# M2003 register map
File version: 1.0
Registers are 32-bit, read-write, reset 0x0 unless marked. A register's access mark holds for its fields unless they carry their own. Offsets are from the block's base; [hi:lo] are bit positions; {n}, {i} and the like mark numbered series.

## TMR2 — TIMER Register Map
Base 0x40051000
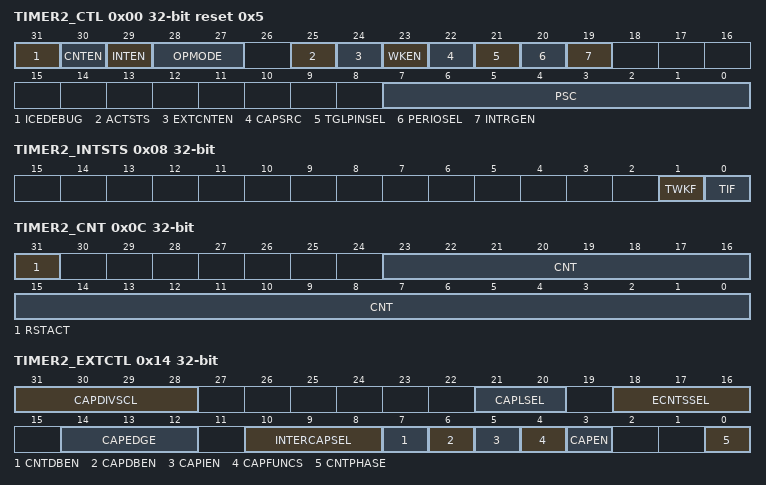
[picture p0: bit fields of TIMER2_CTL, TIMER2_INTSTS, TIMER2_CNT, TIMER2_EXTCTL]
0x00 TIMER2_CTL reset 0x5 — Timer2 Control Register
  [31] ICEDEBUG — ICE Debug Mode Acknowledge Disable Bit (Write Protect). TIMER counter will keep going no matter CPU is held by ICE or not. Note: This bit is write protected. Refer to the SYS_REGLCTL register.
    0=ICE debug mode acknowledgement effects TIMER counting; 1=ICE debug mode acknowledgement Disabled
  [30] CNTEN — Timer Counting Enable Bit. Note 3: Set enable/disable this bit needs 2 * TMR_CLK period to become active, user can read ACTSTS (TIMERx_CTL[25]) to check enable/disable command is completed or not.
    0=Stops/Suspends counting; 1=Starts counting
  [29] INTEN — Timer Interrupt Enable Bit. Note: If this bit is enabled, when the timer time-out interrupt flag TIF is set to 1, the timer interrupt signal is generated and inform to CPU.
    0=Timer time-out interrupt Disabled; 1=Timer time-out interrupt Enabled
  [28:27] OPMODE — Timer Counting Mode Select
    0=The timer controller is operated in One-shot mode; 1=The timer controller is operated in Periodic mode; 2=The timer controller is operated in Toggle-output mode; 3=The timer controller is operated in Continuous Counting mode
  [25] ACTSTS ro — Timer Active Status Bit (Read Only). This bit indicates the 24-bit up counter status. Note: This bit may active when CNT 0 transition to CNT 1.
    0=24-bit up counter is not active; 1=24-bit up counter is active
  [24] EXTCNTEN — Event Counter Mode Enable Bit. This bit is for external counting pin function enabled. Note: When timer is used as an event counter, this bit should be set to 1 and select PCLK as timer clock source.
    0=Event counter mode Disabled; 1=Event counter mode Enabled
  [23] WKEN — Wake-up Function Enable Bit. If this bit is set to 1, while timer interrupt flag TIF (TIMERx_INTSTS[0]) is 1 and INTEN (TIMERx_CTL[29]) is enabled, the timer interrupt signal will generate a wake-up trigger event to CPU.
    0=Wake-up function Disabled if timer interrupt signal generated; 1=Wake-up function Enabled if timer interrupt signal generated
  [22] CAPSRC — Capture Pin Source Selection. Note: Set this bit to 0 .
    0=Capture Function source is from TMx_EXT (x= 0~3) pin
  [21] TGLPINSEL — Toggle-output Pin Select
    0=Toggle mode output to TMx (Timer Event Counter Pin); 1=Toggle mode output to TMx_EXT (Timer External Capture Pin)
  [20] PERIOSEL — Periodic Mode Behavior Selection Enable Bit. If updated CMPDAT value CNT, CNT will be reset to default value.
    0=The behavior selection in periodic mode is Disabled; 1=The behavior selection in periodic mode is Enabled
  [19] INTRGEN — Inter-timer Trigger Mode Enable Bit. Setting this bit will enable the inter-timer trigger capture function. The Timer0/2 will be in event counter mode and counting with external clock source or event.Also, Timer1/3 will be in trigger-counting mode of capture function. Note: For Timer1/3, this bit is ineffective and the read back value is always 0.
    0=Inter-Timer Trigger Capture mode Disabled; 1=Inter-Timer Trigger Capture mode Enabled
  [7:0] PSC — Prescale Counter. Note: Update prescale counter value will reset internal 8-bit prescale counter and 24-bit up counter value.
0x04 TIMER2_CMP — Timer2 Comparator Register
  [23:0] CMPDAT — Timer Comparator Value. CMPDAT is a 24-bit compared value register. When the internal 24-bit up counter value is equal to CMPDAT value, the TIF (TIMERx_INTSTS[0] Timer Interrupt Flag) will set to 1. Note 1: Never write 0x0 or 0x1 in CMPDAT field, or the core will run into unknown state. Note 2: When timer is operating at continuous counting mode, the 24-bit up counter will keep counting continuously even if user writes a new value into CMPDAT field. But if timer is operating at other modes, the 24-bit up counter will restart counting from 0 and using newest CMPDAT value to be the timer compared value while user writes a new value into CMPDAT field.
0x08 TIMER2_INTSTS — Timer2 Interrupt Status Register
  [1] TWKF — Timer Wake-up Flag. This bit indicates the interrupt wake-up flag status of timer. Note: This bit is cleared by writing 1 to it.
    0=Timer does not cause CPU wake-up; 1=CPU wake-up from Idle or Power-down mode if timer time-out interrupt signal generated
  [0] TIF — Timer Interrupt Flag. This bit indicates the interrupt flag status of Timer while 24-bit timer up counter CNT (TIMERx_CNT[23:0]) value reaches to CMPDAT (TIMERx_CMP[23:0]) value. Note: This bit is cleared by writing 1 to it.
    0=No effect; 1=CNT value matches the CMPDAT value
0x0C TIMER2_CNT — Timer2 Data Register
  [31] RSTACT ro — Timer Data Register Reset Active (Read Only). This bit indicates if the counter reset operation active. When user writes this CNT register, timer starts to reset its internal 24-bit timer up-counter to 0 and reload 8-bit pre-scale counter. At the same time, timer set this flag to 1 to indicate the counter reset operation is in progress. Once the counter reset operation done, timer clear this bit to 0 automatically.
    0=Reset operation is done; 1=Reset operation triggered by writing TIMERx_CNT is in progress
  [23:0] CNT — Timer Data Register. Read operation. Read this register to get CNT value. For example: If EXTCNTEN (TIMERx_CTL[24]) is 0, user can read CNT value for getting current 24-bit counter value. If EXTCNTEN (TIMERx_CTL[24]) is 1, user can read CNT value for getting current 24-bit event input counter value. Write operation. Writing any value to this register will reset current CNT value to 0 and reload internal 8-bit prescale counter.
0x10 TIMER2_CAP ro — Timer2 Capture Data Register
  [23:0] CAPDAT — Timer Capture Data Register. When CAPEN (TIMERx_EXTCTL[3]) bit is set, CAPFUNCS (TIMERx_EXTCTL[4]) bit is 0, and a transition on TMx_EXT pin matched the CAPEDGE (TIMERx_EXTCTL[14:12]) setting, CAPIF (TIMERx_EINTSTS[0]) will set to 1 and the current timer counter value CNT (TIMERx_CNT[23:0]) will be auto-loaded into this CAPDAT field.
0x14 TIMER2_EXTCTL — Timer2 External Control Register
  [31:28] CAPDIVSCL — Timer Capture Source Divider Scale. This bits indicate the divide scale for capture source divider. Note: Set INTERCAPSEL (TIMERx_EXTCTL[10:8]) and CAPSRC (TIMERx_CTL[22]) to select capture source.
    0=Capture source/1; 1=Capture source/2; 2=Capture source/4; 3=Capture source/8; 4=Capture source/16; 5=Capture source/32; 6=Capture source/64; 7=Capture source/128; 8=Capture source/256
  [21:20] CAPLSEL — Capture Trigger Length Selection. Note: This function is exclusively operational in Timer0 and Timer2.
    {v}=TMx_EXT (x= 0,2) pin input capture length {v+1} selection (v=0..3)
  [18:16] ECNTSSEL — Event Counter Source Selection to Trigger Event Counter Function
    0=Event Counter input source is from external TMx (x= 0~3) pin
  [14:12] CAPEDGE — Timer External Capture Pin Edge Detect. When first capture event is generated, the CNT (TIMERx_CNT[23:0]) will be reset to 0 and first CAPDAT (TIMERx_CAP[23:0]) should be to 0. Note: Set CAPSRC (TIMERx_CTL[22]) and INTERCAPSEL (TIMERx_EXTCTL[10:8]) to select capture source.
    0=Capture event occurred when detect falling edge transfer on TMx_EXT (x= 0~3) pin; 1=Capture event occurred when detect rising edge transfer on TMx_EXT (x= 0~3) pin; 2=Capture event occurred when detect both falling and rising edge transfer on TMx_EXT (x= 0~3) pin, and first capture event occurred at falling edge transfer; 3=Capture event occurred when detect both rising and falling edge transfer on TMx_EXT (x= 0~3) pin, and first capture event occurred at rising edge transfer; 6=First capture event occurred at falling edge, follows capture events are at rising edge transfer on TMx_EXT (x= 0~3) pin; 7=First capture event occurred at rising edge, follows capture events are at falling edge transfer on TMx_EXT (x= 0~3) pin
  [10:8] INTERCAPSEL — Internal Capture Source Select. Note: 000 and 001 are only available when CAPSRC (TIMERx_CTL[22]) is 0.
    0=Capture Function source is from TMx_EXT (x=0~3) pin; 1=Capture Function source is from TMx_EXT (x=0~3) pin; 4=Capture Function source is from HIRC; 5=Capture Function source is from LIRC
  [7] CNTDBEN — Timer Counter Pin De-bounce Enable Bit. Note: If this bit is enabled, the edge detection of TMx pin is detected with de-bounce circuit.
    0=TMx (x= 0~3) pin de-bounce Disabled; 1=TMx (x= 0~3) pin de-bounce Enabled
  [6] CAPDBEN — Timer External Capture Pin De-bounce Enable Bit. Note: If this bit is enabled, the edge detection of TMx_EXT pin is detected with de-bounce circuit.
    0=TMx_EXT (x= 0~3) pin de-bounce Disabled; 1=TMx_EXT (x= 0~3) pin de-bounce Enabled
  [5] CAPIEN — Timer External Capture Interrupt Enable Bit
    0=TMx_EXT (x= 0~3) pin, internal clock, or external clock detection Interrupt Disabled; 1=TMx_EXT (x= 0~3) pin, internal clock, or external clock detection Interrupt Enabled
  [4] CAPFUNCS — Capture Function Selection
    0=External Capture Mode Enabled; 1=External Reset Mode Enabled
  [3] CAPEN — Timer Capture Enable Bit. This bit enables the capture input function. Note: When CAPEN is 1, user can set INTERCAPSEL (TIMERx_EXTCTL [10:8]) to select capture source.
    0=Capture source Disabled; 1=Capture source Enabled
  [0] CNTPHASE — Timer External Count Phase
    0=A falling edge of external counting pin will be counted; 1=A rising edge of external counting pin will be counted
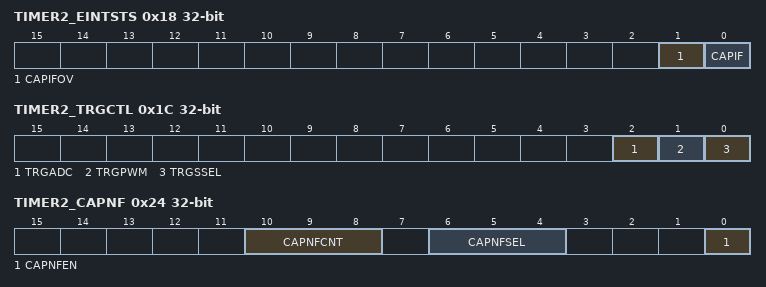
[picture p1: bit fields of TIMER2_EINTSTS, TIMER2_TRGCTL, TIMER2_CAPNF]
0x18 TIMER2_EINTSTS — Timer2 External Interrupt Status Register
  [1] CAPIFOV ro — Capture Latch Interrupt Flag Overrun Status (Read Only). Note: This bit will be cleared automatically when user clear corresponding CAPIF.
    0=Capture latch happened when the corresponding CAPIF is 0; 1=Capture latch happened when the corresponding CAPIF is 1
  [0] CAPIF — Timer External Capture Interrupt Flag. This bit indicates the timer external capture interrupt flag status. Note 3: There is a new incoming capture event detected before CPU clearing the CAPIF status. If the above condition occurred, the Timer will keep register TIMERx_CAP unchanged and drop the new capture value.
    0=TMx_EXT (x= 0~3) pin, internal clock, or external clock interrupt did not occur; 1=TMx_EXT (x= 0~3) pin, internal clock, or external clock interrupt occurred
0x1C TIMER2_TRGCTL — Timer2 Trigger Control Register
  [2] TRGADC — Trigger ADC Enable Bit. If this bit is set to 1, each timer time-out event or capture event can be triggered ADC conversion.
    0=Timer interrupt trigger ADC Disabled; 1=Timer interrupt trigger ADC Enabled
  [1] TRGPWM — Trigger PWM Enable Bit. If this bit is set to 1, each timer time-out event or capture event can be as PWM counter clock source.
    0=Timer interrupt trigger PWM Disabled; 1=Timer interrupt trigger PWM Enabled
  [0] TRGSSEL — Trigger Source Select Bit. This bit is used to select internal trigger source is form timer time-out interrupt signal or capture interrupt signal.
    0=Time-out interrupt signal is used to internal trigger PWM and ADC; 1=Capture interrupt signal is used to internal trigger PWM and ADC
0x24 TIMER2_CAPNF — Timer2 Capture Input Noise Filter Register
  [10:8] CAPNFCNT — Capture Edge Detector Noise Filter Count. These bits control the capture filter counter to count from 0 to CAPNFCNT.
  [6:4] CAPNFSEL — Capture Edge Detector Noise Filter Clock Selection
    0=Noise filter clock is PCLKx; 1=Noise filter clock is PCLKx/2; 2=Noise filter clock is PCLKx/4; 3=Noise filter clock is PCLKx/8; 4=Noise filter clock is PCLKx/16; 5=Noise filter clock is PCLKx/32; 6=Noise filter clock is PCLKx/64; 7=Noise filter clock is PCLKx/128
  [0] CAPNFEN — Capture Noise Filter Enable
    0=Capture Noise Filter function Disabled; 1=Capture Noise Filter function Enabled
{0x74+4i} TIMER2_CAP{i} ro (i=1..3) — Timer2 Capture Data {i} Register
  [23:0] CAPDATn — Timer Capture Data n Register. When CAPEN (TIMERx_EXTCTL[3]) bit is set and CAPLSEL(TIMERx_EXTCTL[21:20]) not equal to 00b, CAPFUNCS (TIMERx_EXTCTL[4]) bit is 0, and a transition on TMx_EXT pin matched the CAPEDGE (TIMERx_EXTCTL[14:12]) setting, the current timer counter value CNT (TIMERx_CNT[23:0]) will be auto-loaded into this CAPDATn field.
